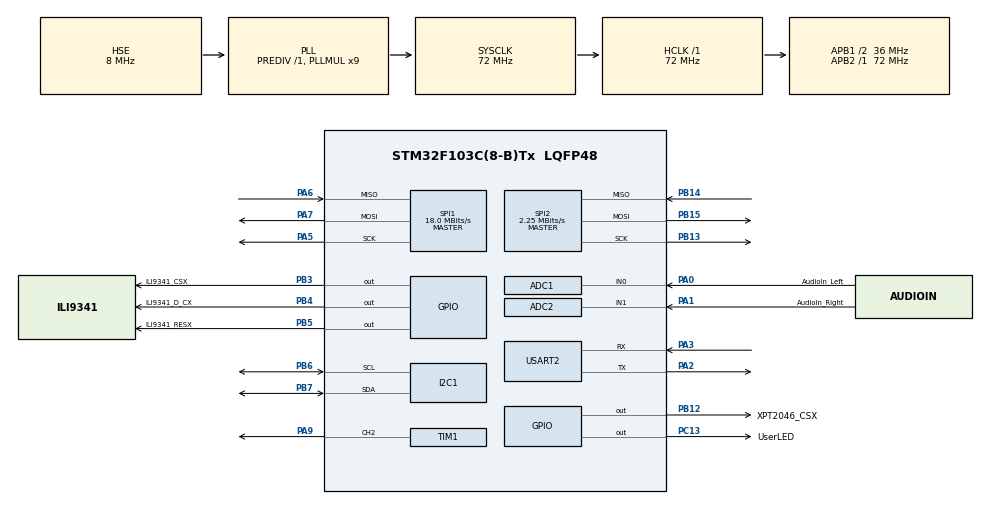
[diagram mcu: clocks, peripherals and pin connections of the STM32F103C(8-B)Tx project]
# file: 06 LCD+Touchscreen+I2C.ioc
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ADC1.Channel-23\#ChannelRegularConversion=ADC_CHANNEL_0
ADC1.ContinuousConvMode=DISABLE
ADC1.DataAlign=ADC_DATAALIGN_RIGHT
ADC1.DiscontinuousConvMode=DISABLE
ADC1.EnableAnalogWatchDog=false
ADC1.EnableRegularConversion=ENABLE
ADC1.ExternalTrigConv=ADC_EXTERNALTRIGCONV_T3_TRGO
ADC1.InjNumberOfConversion=0
ADC1.Mode=ADC_DUALMODE_REGSIMULT
ADC1.NbrOfConversion=1
ADC1.NbrOfConversionFlag=1
ADC1.Rank-23\#ChannelRegularConversion=1
ADC1.SamplingTime-23\#ChannelRegularConversion=ADC_SAMPLETIME_13CYCLES_5
ADC1.ScanConvMode=ADC_SCAN_DISABLE
ADC1.master=1
ADC2.Channel-0\#ChannelRegularConversion=ADC_CHANNEL_1
ADC2.ContinuousConvMode=DISABLE
ADC2.DataAlign=ADC_DATAALIGN_RIGHT
ADC2.DiscontinuousConvMode=DISABLE
ADC2.EnableAnalogWatchDog=false
ADC2.EnableRegularConversion=ENABLE
ADC2.InjNumberOfConversion=0
ADC2.Mode=ADC_DUALMODE_REGSIMULT
ADC2.NbrOfConversion=1
ADC2.NbrOfConversionFlag=1
ADC2.Rank-0\#ChannelRegularConversion=1
ADC2.SamplingTime-0\#ChannelRegularConversion=ADC_SAMPLETIME_13CYCLES_5
ADC2.ScanConvMode=ADC_SCAN_DISABLE
Dma.ADC1.1.Direction=DMA_PERIPH_TO_MEMORY
Dma.ADC1.1.Instance=DMA1_Channel1
Dma.ADC1.1.MemDataAlignment=DMA_MDATAALIGN_WORD
Dma.ADC1.1.MemInc=DMA_MINC_ENABLE
Dma.ADC1.1.Mode=DMA_NORMAL
Dma.ADC1.1.PeriphDataAlignment=DMA_PDATAALIGN_WORD
Dma.ADC1.1.PeriphInc=DMA_PINC_DISABLE
Dma.ADC1.1.Priority=DMA_PRIORITY_HIGH
Dma.Request0=SPI1_TX
Dma.Request1=ADC1
Dma.SPI1_TX.0.Direction=DMA_MEMORY_TO_PERIPH
Dma.SPI1_TX.0.Instance=DMA1_Channel3
Dma.SPI1_TX.0.MemDataAlignment=DMA_MDATAALIGN_BYTE
Dma.SPI1_TX.0.MemInc=DMA_MINC_ENABLE
Dma.SPI1_TX.0.Mode=DMA_NORMAL
Dma.SPI1_TX.0.PeriphDataAlignment=DMA_PDATAALIGN_BYTE
Dma.SPI1_TX.0.PeriphInc=DMA_PINC_DISABLE
Dma.SPI1_TX.0.Priority=DMA_PRIORITY_HIGH
Mcu.Family=STM32F1
Mcu.Name=STM32F103C(8-B)Tx
Mcu.Package=LQFP48
NVIC.DMA1_Channel1_IRQn=true\:0\:0\:false\:false\:true\:false\:true\:true
NVIC.DMA1_Channel3_IRQn=true\:0\:0\:false\:false\:true\:false\:true\:true
NVIC.PriorityGroup=NVIC_PRIORITYGROUP_4
PA0-WKUP.GPIO_Label=AudioIn_Left
PA0-WKUP.Signal=ADCx_IN0
PA1.GPIO_Label=AudioIn_Right
PA1.Signal=ADCx_IN1
PA13.Mode=Serial_Wire
PA13.Signal=SYS_JTMS-SWDIO
PA14.Mode=Serial_Wire
PA14.Signal=SYS_JTCK-SWCLK
PA2.Mode=Asynchronous
PA2.Signal=USART2_TX
PA3.Mode=Asynchronous
PA3.Signal=USART2_RX
PA5.Mode=Full_Duplex_Master
PA5.Signal=SPI1_SCK
PA6.Mode=Full_Duplex_Master
PA6.Signal=SPI1_MISO
PA7.Mode=Full_Duplex_Master
PA7.Signal=SPI1_MOSI
PA9.Signal=S_TIM1_CH2
PB12.GPIO_Label=XPT2046_CSX
PB12.GPIO_Speed=GPIO_SPEED_FREQ_HIGH
PB12.PinState=GPIO_PIN_SET
PB12.Signal=GPIO_Output
PB13.Mode=Full_Duplex_Master
PB13.Signal=SPI2_SCK
PB14.Mode=Full_Duplex_Master
PB14.Signal=SPI2_MISO
PB15.Mode=Full_Duplex_Master
PB15.Signal=SPI2_MOSI
PB3.GPIO_Label=ILI9341_CSX
PB3.GPIO_Speed=GPIO_SPEED_FREQ_HIGH
PB3.PinState=GPIO_PIN_SET
PB3.Signal=GPIO_Output
PB4.GPIO_Label=ILI9341_D_CX
PB4.GPIO_Speed=GPIO_SPEED_FREQ_HIGH
PB4.PinState=GPIO_PIN_SET
PB4.Signal=GPIO_Output
PB5.GPIO_Label=ILI9341_RESX
PB5.GPIO_Speed=GPIO_SPEED_FREQ_HIGH
PB5.PinState=GPIO_PIN_RESET
PB5.Signal=GPIO_Output
PB6.GPIO_Pu=GPIO_PULLUP
PB6.Mode=I2C
PB6.Signal=I2C1_SCL
PB7.GPIO_Pu=GPIO_PULLUP
PB7.Mode=I2C
PB7.Signal=I2C1_SDA
PC13-TAMPER-RTC.GPIO_Label=UserLED
PC13-TAMPER-RTC.PinState=GPIO_PIN_SET
PC13-TAMPER-RTC.Signal=GPIO_Output
PD0-OSC_IN.Mode=HSE-External-Oscillator
PD0-OSC_IN.Signal=RCC_OSC_IN
PD1-OSC_OUT.Mode=HSE-External-Oscillator
PD1-OSC_OUT.Signal=RCC_OSC_OUT
ProjectManager.HeapSize=0x200
ProjectManager.StackSize=0x400
ProjectManager.TargetToolchain=STM32CubeIDE
RCC.ADCPresc=RCC_ADCPCLK2_DIV6
RCC.AHBFreq_Value=72000000
RCC.APB1CLKDivider=RCC_HCLK_DIV2
RCC.APB1Freq_Value=36000000
RCC.APB1TimFreq_Value=72000000
RCC.APB2Freq_Value=72000000
RCC.APB2TimFreq_Value=72000000
RCC.HCLKFreq_Value=72000000
RCC.PLLMUL=RCC_PLL_MUL9
RCC.PLLSourceVirtual=RCC_PLLSOURCE_HSE
RCC.SYSCLKFreq_VALUE=72000000
RCC.SYSCLKSource=RCC_SYSCLKSOURCE_PLLCLK
RCC.USBFreq_Value=72000000
SH.ADCx_IN0.0=ADC1_IN0,IN0
SH.ADCx_IN1.0=ADC2_IN1,IN1
SH.S_TIM1_CH2.0=TIM1_CH2,PWM Generation2 CH2
SPI1.BaudRatePrescaler=SPI_BAUDRATEPRESCALER_4
SPI1.CalculateBaudRate=18.0 MBits/s
SPI1.DataSize=SPI_DATASIZE_8BIT
SPI1.Direction=SPI_DIRECTION_2LINES
SPI1.Mode=SPI_MODE_MASTER
SPI1.VirtualType=VM_MASTER
SPI2.BaudRatePrescaler=SPI_BAUDRATEPRESCALER_16
SPI2.CalculateBaudRate=2.25 MBits/s
SPI2.Direction=SPI_DIRECTION_2LINES
SPI2.Mode=SPI_MODE_MASTER
SPI2.VirtualType=VM_MASTER
TIM1.Channel-PWM\ Generation2\ CH2=TIM_CHANNEL_2
TIM1.Period=19
TIM1.Prescaler=3599
TIM1.Pulse-PWM\ Generation2\ CH2=10
TIM3.Period=9
TIM3.Prescaler=359
TIM3.TIM_MasterOutputTrigger=TIM_TRGO_UPDATE
USART2.VirtualMode=VM_ASYNC
VP_TIM1_VS_ClockSourceINT.Mode=Internal
VP_TIM3_VS_ClockSourceINT.Mode=Internal
board=CubeMX LCD+Touchscreen+I2C

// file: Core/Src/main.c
/* USER CODE BEGIN Header */
/**
  ******************************************************************************
  * @file           : main.c
  * @brief          : Main program body
  ******************************************************************************
  * @attention
  *
  * Copyright (c) 2025 STMicroelectronics.
  * All rights reserved.
  *
  * This software is licensed under terms that can be found in the LICENSE file
  * in the root directory of this software component.
  * If no LICENSE file comes with this software, it is provided AS-IS.
  *
  ******************************************************************************
  */
/* USER CODE END Header */
#include "main.h"
#include "adc.h"
#include "dma.h"
#include "i2c.h"
#include "spi.h"
#include "tim.h"
#include "usart.h"
#include "gpio.h"

/* USER CODE BEGIN Includes */

#include "JSB_ILI9341.h"
#include "JSB_XPT2046.h"
#include "go.h"

/* USER CODE END Includes */

/* USER CODE BEGIN PV */
/* Private variables ---------------------------------------------------------*/

/* USER CODE END PV */

void SystemClock_Config(void);
/* USER CODE BEGIN PFP */
/* Private function prototypes -----------------------------------------------*/

/* USER CODE END PFP */

int main(void)
{

  /* MCU Configuration--------------------------------------------------------*/

  /* Reset of all peripherals, Initializes the Flash interface and the Systick. */
  HAL_Init();

  /* Configure the system clock */
  SystemClock_Config();

  /* USER CODE BEGIN SysInit */

  // Check clock speed:
  uint32_t hclk = HAL_RCC_GetHCLKFreq();
  if (hclk != 72000000)
    Error_Handler();

  /* USER CODE END SysInit */

  /* Initialize all configured peripherals */
  MX_GPIO_Init();
  MX_DMA_Init();
  MX_USART2_UART_Init();
  MX_SPI1_Init();
  MX_SPI2_Init();
  MX_ADC1_Init();
  MX_TIM3_Init();
  MX_TIM1_Init();
  MX_ADC2_Init();
  MX_I2C1_Init();
  /* USER CODE BEGIN 2 */

  ILI9341_Initialize(&hspi1, 0);
  XPT2046_Initialize(&hspi2);

  HAL_TIM_Base_Start(&htim3); // ADC timer.

  /* USER CODE END 2 */

  /* Infinite loop */
  /* USER CODE BEGIN WHILE */
  Go();
    /* USER CODE END WHILE */

}

void SystemClock_Config(void)
{
  RCC_OscInitTypeDef RCC_OscInitStruct = {0};
  RCC_ClkInitTypeDef RCC_ClkInitStruct = {0};
  RCC_PeriphCLKInitTypeDef PeriphClkInit = {0};

  /** Initializes the RCC Oscillators according to the specified parameters
  * in the RCC_OscInitTypeDef structure.
  */
  RCC_OscInitStruct.OscillatorType = RCC_OSCILLATORTYPE_HSE;
  RCC_OscInitStruct.HSEState = RCC_HSE_ON;
  RCC_OscInitStruct.HSEPredivValue = RCC_HSE_PREDIV_DIV1;
  RCC_OscInitStruct.HSIState = RCC_HSI_ON;
  RCC_OscInitStruct.PLL.PLLState = RCC_PLL_ON;
  RCC_OscInitStruct.PLL.PLLSource = RCC_PLLSOURCE_HSE;
  RCC_OscInitStruct.PLL.PLLMUL = RCC_PLL_MUL9;
  if (HAL_RCC_OscConfig(&RCC_OscInitStruct) != HAL_OK)
  {
    Error_Handler();
  }

  /** Initializes the CPU, AHB and APB buses clocks
  */
  RCC_ClkInitStruct.ClockType = RCC_CLOCKTYPE_HCLK|RCC_CLOCKTYPE_SYSCLK
                              |RCC_CLOCKTYPE_PCLK1|RCC_CLOCKTYPE_PCLK2;
  RCC_ClkInitStruct.SYSCLKSource = RCC_SYSCLKSOURCE_PLLCLK;
  RCC_ClkInitStruct.AHBCLKDivider = RCC_SYSCLK_DIV1;
  RCC_ClkInitStruct.APB1CLKDivider = RCC_HCLK_DIV2;
  RCC_ClkInitStruct.APB2CLKDivider = RCC_HCLK_DIV1;

  if (HAL_RCC_ClockConfig(&RCC_ClkInitStruct, FLASH_LATENCY_2) != HAL_OK)
  {
    Error_Handler();
  }
  PeriphClkInit.PeriphClockSelection = RCC_PERIPHCLK_ADC;
  PeriphClkInit.AdcClockSelection = RCC_ADCPCLK2_DIV6;
  if (HAL_RCCEx_PeriphCLKConfig(&PeriphClkInit) != HAL_OK)
  {
    Error_Handler();
  }
}

void Error_Handler(void)
{
  /* USER CODE BEGIN Error_Handler_Debug */
  /* User can add his own implementation to report the HAL error return state */
  while (1)
  {
    HAL_GPIO_WritePin(UserLED_GPIO_Port, UserLED_Pin, GPIO_PIN_SET);
    HAL_Delay(100);
    HAL_GPIO_WritePin(UserLED_GPIO_Port, UserLED_Pin, GPIO_PIN_RESET);
    HAL_Delay(100);
  }
  /* USER CODE END Error_Handler_Debug */
}
